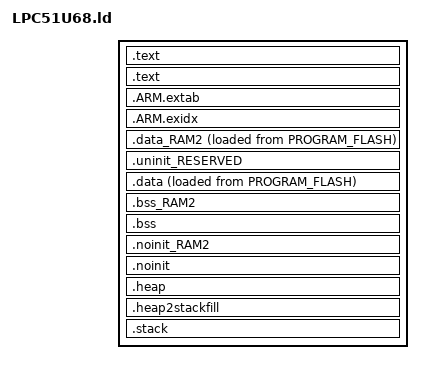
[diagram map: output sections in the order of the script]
/*
 * GENERATED FILE - DO NOT EDIT
 * Copyright (c) 2008-2013 Code Red Technologies Ltd,
 * Copyright 2015, 2018-2019 NXP
 * (c) NXP Semiconductors 2013-2021
 * Generated linker script file for LPC51U68
 * Created from linkscript.ldt by FMCreateLinkLibraries
 * Using Freemarker v2.3.23
 * MCUXpresso IDE v11.2.1 [Build 4149] [2020-10-07] on 02/01/2021 11:02:27
 */
INCLUDE "LPC51U68_library.ld"
INCLUDE "LPC51U68_memory.ld"


ENTRY(ResetISR)

SECTIONS
{
     /* MAIN TEXT SECTION */
    .text : ALIGN(4)
    {
        FILL(0xff)
        __vectors_start__ = ABSOLUTE(.) ;
        KEEP(*(.isr_vector))
        /* Global Section Table */
        . = ALIGN(4) ;
        __section_table_start = .;
        __data_section_table = .;
        LONG(LOADADDR(.data));
        LONG(    ADDR(.data));
        LONG(  SIZEOF(.data));
        LONG(LOADADDR(.data_RAM2));
        LONG(    ADDR(.data_RAM2));
        LONG(  SIZEOF(.data_RAM2));
        __data_section_table_end = .;
        __bss_section_table = .;
        LONG(    ADDR(.bss));
        LONG(  SIZEOF(.bss));
        LONG(    ADDR(.bss_RAM2));
        LONG(  SIZEOF(.bss_RAM2));
        __bss_section_table_end = .;
        __section_table_end = . ;
        /* End of Global Section Table */

        *(.after_vectors*)

        /* Code Read Protection data */
        . = 0x2fc ;
        PROVIDE(__CRP_WORD_START__ = .) ;
        KEEP(*(.crp))
        PROVIDE(__CRP_WORD_END__ = .) ;
        ASSERT(!(__CRP_WORD_START__ == __CRP_WORD_END__), "Linker CRP Enabled, but no CRP_WORD provided within application");
        /* End of Code Read Protection */
    } > PROGRAM_FLASH

    .text : ALIGN(4)
    {
       *(.text*)
       KEEP(*freertos*/tasks.o(.rodata*)) /* FreeRTOS Debug Config */
       *(.rodata .rodata.* .constdata .constdata.*)
       . = ALIGN(4);
    } > PROGRAM_FLASH
    /*
     * for exception handling/unwind - some Newlib functions (in common
     * with C++ and STDC++) use this.
     */
    .ARM.extab : ALIGN(4)
    {
        *(.ARM.extab* .gnu.linkonce.armextab.*)
    } > PROGRAM_FLASH

    .ARM.exidx : ALIGN(4)
    {
        __exidx_start = .;
        *(.ARM.exidx* .gnu.linkonce.armexidx.*)
        __exidx_end = .;
    } > PROGRAM_FLASH
 
    _etext = .;
        
    /* DATA section for SRAMX */

    .data_RAM2 : ALIGN(4)
    {
        FILL(0xff)
        PROVIDE(__start_data_RAM2 = .) ;
        PROVIDE(__start_data_SRAMX = .) ;
        *(.ramfunc.$RAM2)
        *(.ramfunc.$SRAMX)
        *(.data.$RAM2)
        *(.data.$SRAMX)
        *(.data.$RAM2.*)
        *(.data.$SRAMX.*)
        . = ALIGN(4) ;
        PROVIDE(__end_data_RAM2 = .) ;
        PROVIDE(__end_data_SRAMX = .) ;
     } > SRAMX AT>PROGRAM_FLASH

    /* MAIN DATA SECTION */
    .uninit_RESERVED (NOLOAD) : ALIGN(4)
    {
        _start_uninit_RESERVED = .;
        KEEP(*(.bss.$RESERVED*))
       . = ALIGN(4) ;
        _end_uninit_RESERVED = .;
    } > SRAM0 AT> SRAM0

    /* Main DATA section (SRAM0) */
    .data : ALIGN(4)
    {
       FILL(0xff)
       _data = . ;
       PROVIDE(__start_data_RAM = .) ;
       PROVIDE(__start_data_SRAM0 = .) ;
       *(vtable)
       *(.ramfunc*)
       KEEP(*(CodeQuickAccess))
       KEEP(*(DataQuickAccess))
       *(RamFunction)
       *(.data*)
       . = ALIGN(4) ;
       _edata = . ;
       PROVIDE(__end_data_RAM = .) ;
       PROVIDE(__end_data_SRAM0 = .) ;
    } > SRAM0 AT>PROGRAM_FLASH

    /* BSS section for SRAMX */
    .bss_RAM2 : ALIGN(4)
    {
       PROVIDE(__start_bss_RAM2 = .) ;
       PROVIDE(__start_bss_SRAMX = .) ;
       *(.bss.$RAM2)
       *(.bss.$SRAMX)
       *(.bss.$RAM2.*)
       *(.bss.$SRAMX.*)
       . = ALIGN (. != 0 ? 4 : 1) ; /* avoid empty segment */
       PROVIDE(__end_bss_RAM2 = .) ;
       PROVIDE(__end_bss_SRAMX = .) ;
    } > SRAMX AT> SRAMX

    /* MAIN BSS SECTION */
    .bss : ALIGN(4)
    {
        _bss = .;
        PROVIDE(__start_bss_RAM = .) ;
        PROVIDE(__start_bss_SRAM0 = .) ;
        *(.bss*)
        *(COMMON)
        . = ALIGN(4) ;
        _ebss = .;
        PROVIDE(__end_bss_RAM = .) ;
        PROVIDE(__end_bss_SRAM0 = .) ;
        PROVIDE(end = .);
    } > SRAM0 AT> SRAM0

    /* NOINIT section for SRAMX */
    .noinit_RAM2 (NOLOAD) : ALIGN(4)
    {
       PROVIDE(__start_noinit_RAM2 = .) ;
       PROVIDE(__start_noinit_SRAMX = .) ;
       *(.noinit.$RAM2)
       *(.noinit.$SRAMX)
       *(.noinit.$RAM2.*)
       *(.noinit.$SRAMX.*)
       . = ALIGN(4) ;
       PROVIDE(__end_noinit_RAM2 = .) ;
       PROVIDE(__end_noinit_SRAMX = .) ;
    } > SRAMX AT> SRAMX

    /* DEFAULT NOINIT SECTION */
    .noinit (NOLOAD): ALIGN(4)
    {
        _noinit = .;
        PROVIDE(__start_noinit_RAM = .) ;
        PROVIDE(__start_noinit_SRAM0 = .) ;
        *(.noinit*)
         . = ALIGN(4) ;
        _end_noinit = .;
       PROVIDE(__end_noinit_RAM = .) ;
       PROVIDE(__end_noinit_SRAM0 = .) ;        
    } > SRAM0 AT> SRAM0

    /* Reserve and place Heap within memory map */
    _HeapSize = 0x1000;
    .heap :  ALIGN(4)
    {
        _pvHeapStart = .;
        . += _HeapSize;
        . = ALIGN(4);
        _pvHeapLimit = .;
    } > SRAM0

     _StackSize = 0x1000;
     /* Reserve space in memory for Stack */
    .heap2stackfill  :
    {
        . += _StackSize;
    } > SRAM0
    /* Locate actual Stack in memory map */
    .stack ORIGIN(SRAM0) + LENGTH(SRAM0) - _StackSize - 0:  ALIGN(4)
    {
        _vStackBase = .;
        . = ALIGN(4);
        _vStackTop = . + _StackSize;
    } > SRAM0

    /* ## Create checksum value (used in startup) ## */
    PROVIDE(__valid_user_code_checksum = 0 - 
                                         (_vStackTop 
                                         + (ResetISR + 1) 
                                         + (( DEFINED(NMI_Handler) ? NMI_Handler : M0_NMI_Handler ) + 1) 
                                         + (( DEFINED(HardFault_Handler) ? HardFault_Handler : M0_HardFault_Handler ) + 1) 
                                         )
           );

    /* Provide basic symbols giving location and size of main text
     * block, including initial values of RW data sections. Note that
     * these will need extending to give a complete picture with
     * complex images (e.g multiple Flash banks).
     */
    _image_start = LOADADDR(.text);
    _image_end = LOADADDR(.data) + SIZEOF(.data);
    _image_size = _image_end - _image_start;
}
